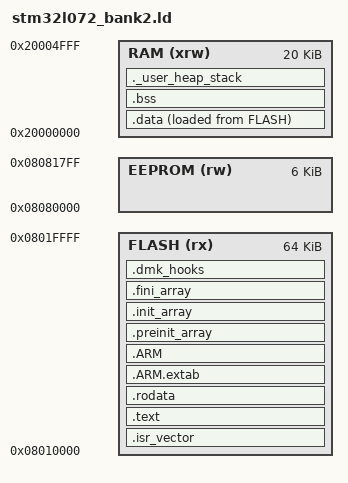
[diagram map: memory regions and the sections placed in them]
/*
 * Linker script for STM32L072RB - Bank 2 (HHKB Classic)
 * Flash: 64 KB starting at 0x08010000
 * RAM:   20 KB starting at 0x20000000
 */

ENTRY(Reset_Handler)

_estack = ORIGIN(RAM) + LENGTH(RAM);

_Min_Heap_Size = 0x800;  /* 2 KB */
_Min_Stack_Size = 0x800; /* 2 KB */

MEMORY
{
    FLASH (rx)      : ORIGIN = 0x08010000, LENGTH = 64K
    RAM   (xrw)     : ORIGIN = 0x20000000, LENGTH = 20K
    EEPROM (rw)     : ORIGIN = 0x08080000, LENGTH = 6K
}

SECTIONS
{
    .isr_vector :
    {
        . = ALIGN(4);
        KEEP(*(.isr_vector))
        . = ALIGN(4);
    } >FLASH

    .text :
    {
        . = ALIGN(4);
        *(.text)
        *(.text*)
        *(.glue_7)
        *(.glue_7t)
        *(.eh_frame)

        KEEP (*(.init))
        KEEP (*(.fini))

        . = ALIGN(4);
        _etext = .;
    } >FLASH

    .rodata :
    {
        . = ALIGN(4);
        *(.rodata)
        *(.rodata*)
        . = ALIGN(4);
    } >FLASH

    .ARM.extab :
    {
        *(.ARM.extab* .gnu.linkonce.armextab.*)
    } >FLASH

    .ARM :
    {
        __exidx_start = .;
        *(.ARM.exidx*)
        __exidx_end = .;
    } >FLASH

    .preinit_array :
    {
        PROVIDE_HIDDEN (__preinit_array_start = .);
        KEEP (*(.preinit_array*))
        PROVIDE_HIDDEN (__preinit_array_end = .);
    } >FLASH

    .init_array :
    {
        PROVIDE_HIDDEN (__init_array_start = .);
        KEEP (*(SORT(.init_array.*)))
        KEEP (*(.init_array*))
        PROVIDE_HIDDEN (__init_array_end = .);
    } >FLASH

    .fini_array :
    {
        PROVIDE_HIDDEN (__fini_array_start = .);
        KEEP (*(SORT(.fini_array.*)))
        KEEP (*(.fini_array*))
        PROVIDE_HIDDEN (__fini_array_end = .);
    } >FLASH

    .dmk_hooks :
    {
        . = ALIGN(4);
        __dmk_hooks_start = .;
        KEEP(*(.dmk_hooks*))
        __dmk_hooks_end = .;
    } >FLASH

    _sidata = LOADADDR(.data);

    .data :
    {
        . = ALIGN(4);
        _sdata = .;
        *(.data)
        *(.data*)
        . = ALIGN(4);
        _edata = .;
    } >RAM AT> FLASH

    . = ALIGN(4);
    .bss :
    {
        _sbss = .;
        __bss_start__ = _sbss;
        *(.bss)
        *(.bss*)
        *(COMMON)
        . = ALIGN(4);
        _ebss = .;
        __bss_end__ = _ebss;
    } >RAM

    ._user_heap_stack :
    {
        . = ALIGN(8);
        PROVIDE ( end = . );
        PROVIDE ( _end = . );
        . = . + _Min_Heap_Size;
        . = . + _Min_Stack_Size;
        . = ALIGN(8);
    } >RAM

    /DISCARD/ :
    {
        libc.a ( * )
        libm.a ( * )
        libgcc.a ( * )
    }
}
